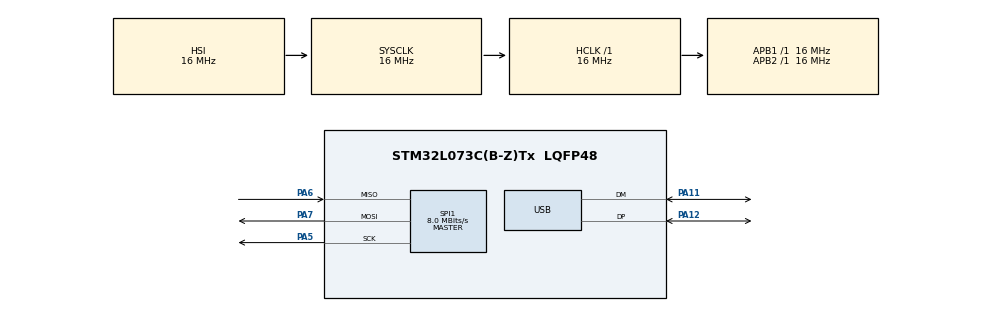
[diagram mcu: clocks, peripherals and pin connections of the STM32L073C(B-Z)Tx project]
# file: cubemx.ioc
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Mcu.Family=STM32L0
Mcu.Name=STM32L073C(B-Z)Tx
Mcu.Package=LQFP48
PA11.Mode=Device
PA11.Signal=USB_DM
PA12.Mode=Device
PA12.Signal=USB_DP
PA13.Mode=Serial_Wire
PA13.Signal=SYS_SWDIO
PA14.Mode=Serial_Wire
PA14.Signal=SYS_SWCLK
PA5.Mode=Full_Duplex_Master
PA5.Signal=SPI1_SCK
PA6.Mode=Full_Duplex_Master
PA6.Signal=SPI1_MISO
PA7.Mode=Full_Duplex_Master
PA7.Signal=SPI1_MOSI
ProjectManager.HeapSize=0x200
ProjectManager.StackSize=0x400
ProjectManager.TargetToolchain=EWARM V8
RCC.AHBFreq_Value=16000000
RCC.APB1Freq_Value=16000000
RCC.APB1TimFreq_Value=16000000
RCC.APB2Freq_Value=16000000
RCC.APB2TimFreq_Value=16000000
RCC.HCLKFreq_Value=16000000
RCC.HSE_VALUE=8000000
RCC.HSI16_VALUE=16000000
RCC.HSI48MClockSelection=RCC_USBCLKSOURCE_HSI48
RCC.HSI48_VALUE=48000000
RCC.HSI_VALUE=16000000
RCC.LSE_VALUE=32768
RCC.MSI_VALUE=2097000
RCC.PLLMUL=RCC_PLLMUL_6
RCC.SYSCLKFreq_VALUE=16000000
RCC.SYSCLKSource=RCC_SYSCLKSOURCE_HSI
RCC.VCOOutputFreq_Value=96000000
SPI1.CalculateBaudRate=8.0 MBits/s
SPI1.Direction=SPI_DIRECTION_2LINES
SPI1.Mode=SPI_MODE_MASTER
SPI1.VirtualType=VM_MASTER
board=custom

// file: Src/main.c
/* USER CODE BEGIN Header */
/**
  ******************************************************************************
  * @file           : main.c
  * @brief          : Main program body
  ******************************************************************************
  * @attention
  *
  * <h2><center>&copy; Copyright (c) 2019 STMicroelectronics.
  * All rights reserved.</center></h2>
  *
  * This software component is licensed by ST under BSD 3-Clause license,
  * the "License"; You may not use this file except in compliance with the
  * License. You may obtain a copy of the License at:
  *                        opensource.org/licenses/BSD-3-Clause
  *
  ******************************************************************************
  */
/* USER CODE END Header */

#include "main.h"
#include "usb_device.h"

/* USER CODE BEGIN Includes */
#include "usbd_cdc_if.h"

/* USER CODE END Includes */

/* USER CODE BEGIN PD */

/**
 * \brief           Temporary array for dual LED with extracted PWM duty cycles
 *
 * We need LED_CFG_RAW_BYTES_PER_LED bytes for PWM setup to send all bits.
 * Before we can send data for first led, we have to send reset pulse, which must be 50us long.
 * PWM frequency is 800kHz, to achieve 50us, we need to send 40 pulses with 0 duty cycle = make array size MAX(2 * LED_CFG_RAW_BYTES_PER_LED, 40)
 */
//static uint32_t
//tmp_led_data[2 * LED_CFG_RAW_BYTES_PER_LED];
//
//static uint8_t          is_reset_pulse;     /*!< Status if we are sending reset pulse or led data */
//static volatile uint8_t is_updating;        /*!< Is updating in progress? */
//static uint32_t         current_led;        /*!< Current LED number we are sending */
//
//void        led_init(void);
//uint8_t     led_update(uint8_t block);
//
//uint8_t     led_set_color(size_t index, uint8_t r, uint8_t g, uint8_t b);
//uint8_t     led_set_color_all(uint8_t r, uint8_t g, uint8_t b);
//uint8_t     led_set_color_rgb(size_t index, uint32_t rgb);
//uint8_t     led_set_color_all_rgb(uint32_t rgb);

//uint8_t     led_is_update_finished(void);
//uint8_t     led_start_reset_pulse(uint8_t num);

/* USER CODE END PD */

SPI_HandleTypeDef hspi1;

void SystemClock_Config(void);
static void MX_GPIO_Init(void);
static void MX_SPI1_Init(void);

int main(void)
{

  /* MCU Configuration--------------------------------------------------------*/

  /* Reset of all peripherals, Initializes the Flash interface and the Systick. */
  HAL_Init();

  /* Configure the system clock */
  SystemClock_Config();

  /* Initialize all configured peripherals */
  MX_GPIO_Init();
  MX_SPI1_Init();
  MX_USB_DEVICE_Init();
  /* USER CODE BEGIN 2 */

  CDC_ClearRXBuffer();

  /* USER CODE END 2 */

  /* Infinite loop */
  /* USER CODE BEGIN WHILE */
  //uint8_t dts[] = "NODATA\r\n";
  //uint8_t dts_size = 8;

  while (1)
  {
    /*
    if (0 != last_read_line[0]) {
      CDC_Transmit_FS(dts, dts_size);
      //CDC_Transmit_FS(last_read_line, last_read_line_size);
      memset(last_read_line, 0, RXBUFSIZE * sizeof(uint8_t));
    }
    */

    /*
    if ('0' != UserRxBufferFS[0]) {
      CDC_Transmit_FS(UserRxBufferFS, 1);

      / *
      uint16_t i = 0;

      while (0 != UserRxBufferFS[i] && i < APP_RX_DATA_SIZE && i < RXBUFSIZE) {
        rxbuf[rxbufpos] = UserRxBufferFS[i];
        rxbufpos++;

        if (rxbufpos > 1 && '\n' == rxbuf[rxbufpos-1]) {
          //rxbuf[rxbufpos] = 0; // only needed with strcpy (instead of strncpy)
          last_read_line_size = rxbufpos;
          //strcpy((char*)last_read_line, (char*)rxbuf);
          strncpy((char*)last_read_line, (const char*)rxbuf, last_read_line_size);
          rxbufpos = 0;
        }

        i++;
      }
      * /

      CDC_ClearRXBuffer();
    }
    */

    if (0 != last_read_line_size) {
      CDC_Transmit_FS(last_read_line, last_read_line_size);
      last_read_line_size = 0;
      memset(last_read_line, 0, RXBUFSIZE * sizeof(uint8_t));
    }

    /*
    if (UserRxBufferFS[0] != '0') {
      uint8_t len = strlen((char*)UserRxBufferFS);
      CDC_Transmit_FS(UserRxBufferFS, len);
      CDC_ClearRXBuffer();
    } else {
      CDC_Transmit_FS(dts, dts_size);
    }
    */

    //CDC_Transmit_FS(rxbuf, rxbufpos);
    HAL_Delay(1000);

    /* USER CODE END WHILE */

  }
}

void SystemClock_Config(void)
{
  RCC_OscInitTypeDef RCC_OscInitStruct = {0};
  RCC_ClkInitTypeDef RCC_ClkInitStruct = {0};
  RCC_PeriphCLKInitTypeDef PeriphClkInit = {0};

  /** Configure the main internal regulator output voltage
  */
  __HAL_PWR_VOLTAGESCALING_CONFIG(PWR_REGULATOR_VOLTAGE_SCALE1);
  /** Initializes the CPU, AHB and APB busses clocks
  */
  RCC_OscInitStruct.OscillatorType = RCC_OSCILLATORTYPE_HSI|RCC_OSCILLATORTYPE_HSI48;
  RCC_OscInitStruct.HSIState = RCC_HSI_ON;
  RCC_OscInitStruct.HSICalibrationValue = RCC_HSICALIBRATION_DEFAULT;
  RCC_OscInitStruct.HSI48State = RCC_HSI48_ON;
  RCC_OscInitStruct.PLL.PLLState = RCC_PLL_NONE;
  if (HAL_RCC_OscConfig(&RCC_OscInitStruct) != HAL_OK)
  {
    Error_Handler();
  }
  /** Initializes the CPU, AHB and APB busses clocks
  */
  RCC_ClkInitStruct.ClockType = RCC_CLOCKTYPE_HCLK|RCC_CLOCKTYPE_SYSCLK
                              |RCC_CLOCKTYPE_PCLK1|RCC_CLOCKTYPE_PCLK2;
  RCC_ClkInitStruct.SYSCLKSource = RCC_SYSCLKSOURCE_HSI;
  RCC_ClkInitStruct.AHBCLKDivider = RCC_SYSCLK_DIV1;
  RCC_ClkInitStruct.APB1CLKDivider = RCC_HCLK_DIV1;
  RCC_ClkInitStruct.APB2CLKDivider = RCC_HCLK_DIV1;

  if (HAL_RCC_ClockConfig(&RCC_ClkInitStruct, FLASH_LATENCY_0) != HAL_OK)
  {
    Error_Handler();
  }
  PeriphClkInit.PeriphClockSelection = RCC_PERIPHCLK_USB;
  PeriphClkInit.UsbClockSelection = RCC_USBCLKSOURCE_HSI48;
  if (HAL_RCCEx_PeriphCLKConfig(&PeriphClkInit) != HAL_OK)
  {
    Error_Handler();
  }
}

static void MX_SPI1_Init(void)
{

  /* SPI1 parameter configuration*/
  hspi1.Instance = SPI1;
  hspi1.Init.Mode = SPI_MODE_MASTER;
  hspi1.Init.Direction = SPI_DIRECTION_2LINES;
  hspi1.Init.DataSize = SPI_DATASIZE_8BIT;
  hspi1.Init.CLKPolarity = SPI_POLARITY_LOW;
  hspi1.Init.CLKPhase = SPI_PHASE_1EDGE;
  hspi1.Init.NSS = SPI_NSS_SOFT;
  hspi1.Init.BaudRatePrescaler = SPI_BAUDRATEPRESCALER_2;
  hspi1.Init.FirstBit = SPI_FIRSTBIT_MSB;
  hspi1.Init.TIMode = SPI_TIMODE_DISABLE;
  hspi1.Init.CRCCalculation = SPI_CRCCALCULATION_DISABLE;
  hspi1.Init.CRCPolynomial = 7;
  if (HAL_SPI_Init(&hspi1) != HAL_OK)
  {
    Error_Handler();
  }

}

static void MX_GPIO_Init(void)
{

  /* GPIO Ports Clock Enable */
  __HAL_RCC_GPIOA_CLK_ENABLE();

}

void Error_Handler(void)
{
}

/************************ (C) COPYRIGHT STMicroelectronics *****END OF FILE****/
